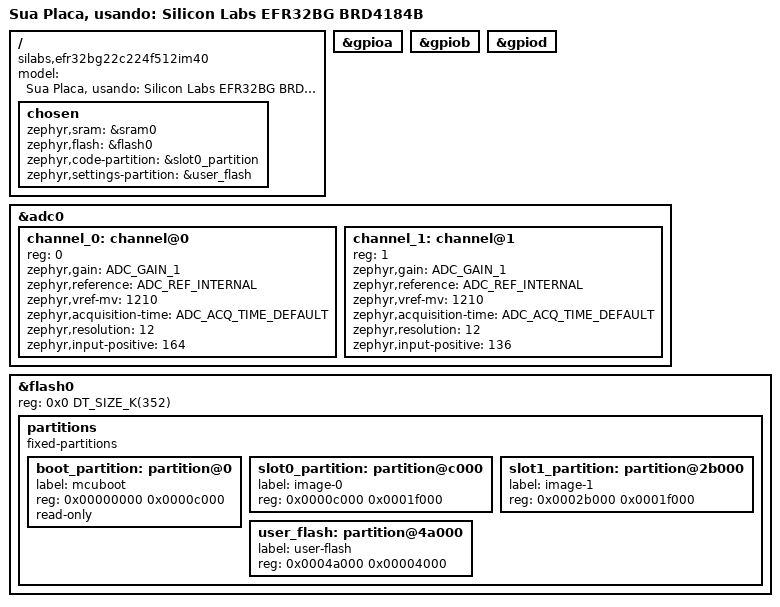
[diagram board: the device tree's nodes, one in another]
/**
 * @file sua-placa.dts
 * @author João Anon (email@edge.ufal.br)
 * @brief Pin Controller para configuração da UART/SPI.
 * @version 0.1
 * @date dd-mm-aaaa
 *
 * @copyright Copyright (c) aaaa
 *
 */

/dts-v1/;
#include <silabs/efr32bg22.dtsi>
#include "sua_placa-pinctrl.dtsi"

/ {
	model = "Sua Placa, usando: Silicon Labs EFR32BG BRD4184B";
	compatible = "silabs,efr32bg22c224f512im40", "silabs,efr32bg_brd4184b",
				 "silabs,efr32bg22";

	chosen {
		zephyr,sram = &sram0;
		zephyr,flash = &flash0;
		zephyr,code-partition = &slot0_partition;
		zephyr,settings-partition = &user_flash;
	};
};

&gpioa {
	status = "okay";
};

&gpiob {
	status = "okay";
};

&gpiod {
	status = "okay";
};

&adc0 {
	#address-cells = <1>;
	#size-cells = <0>;
	status = "okay";

	/* Valor inicial do iadc de cada porta:
	 * PORTA0 128, PORTB0 144, PORTC0 160, PORTD0 176 */

	/* SENSOR_INPUT_VOLTAGE: AC_LEVEL: PC04 */
	channel_0: channel@0 {
		reg = <0>;
		zephyr,gain = "ADC_GAIN_1";
		zephyr,reference = "ADC_REF_INTERNAL";
		zephyr,vref-mv = <1210>;
		zephyr,acquisition-time = <ADC_ACQ_TIME_DEFAULT>;
		zephyr,resolution = <12>;
		zephyr,input-positive = <164>;
	};

	/* SENSOR_OUTPUT_VOLTAGE: SUPPLY_VOLTAGE_ADC: PA08 */
	channel_1: channel@1 {
		reg = <1>;
		zephyr,gain = "ADC_GAIN_1";
		zephyr,reference = "ADC_REF_INTERNAL";
		zephyr,vref-mv = <1210>;
		zephyr,acquisition-time = <ADC_ACQ_TIME_DEFAULT>;
		zephyr,resolution = <12>;
		zephyr,input-positive = <136>;
	};

};

&flash0 {
	reg = <0x0 DT_SIZE_K(352)>;

	partitions {
		#address-cells = <1>;
		#size-cells = <1>;
		compatible = "fixed-partitions";

		/* Reserva 48 KiB para o bootloader */
		boot_partition: partition@0 {
			label = "mcuboot";
			reg = <0x00000000 0x0000c000>;
			read-only;
		};

		/* Reserva 124 KiB para o código no slot0 (Pode ser estendido para a partição no slot1
		 * caso não sejam necessárias atualizações de firmware.) */
		slot0_partition: partition@c000 {
			label = "image-0";
			reg = <0x0000c000 0x0001f000>;
		};

		/* Reserva 124 KiB para atualização de firmware no slot1 */
		slot1_partition: partition@2b000 {
			label = "image-1";
			reg = <0x0002b000 0x0001f000>;
		};

		/* Reserva 16 KiB de espaço para dados do usuário. */
		user_flash: partition@4a000 {
			label = "user-flash";
			reg = <0x0004a000 0x00004000>;
		};
	};
};

